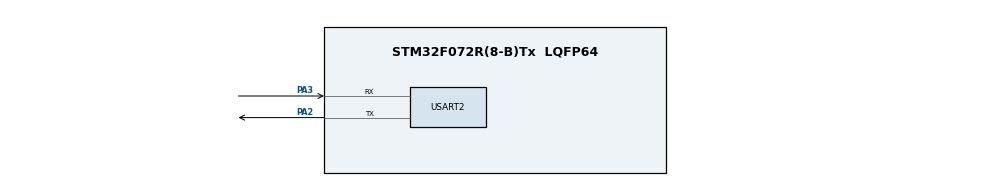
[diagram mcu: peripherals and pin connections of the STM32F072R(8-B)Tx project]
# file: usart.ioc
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Mcu.Family=STM32F0
Mcu.Name=STM32F072R(8-B)Tx
Mcu.Package=LQFP64
NVIC.USART2_IRQn=true\:0\:0\:false\:false\:true\:true\:true
PA2.Mode=Asynchronous
PA2.Signal=USART2_TX
PA3.Mode=Asynchronous
PA3.Signal=USART2_RX
ProjectManager.HeapSize=0x200
ProjectManager.StackSize=0x400
ProjectManager.TargetToolchain=MDK-ARM V5
USART2.VirtualMode-Asynchronous=VM_ASYNC
board=custom

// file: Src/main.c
/* USER CODE BEGIN Header */
/**
  ******************************************************************************
  * @file           : main.c
  * @brief          : Main program body
  ******************************************************************************
  * @attention
  *
  * <h2><center>&copy; Copyright (c) 2020 STMicroelectronics.
  * All rights reserved.</center></h2>
  *
  * This software component is licensed by ST under BSD 3-Clause license,
  * the "License"; You may not use this file except in compliance with the
  * License. You may obtain a copy of the License at:
  *                        opensource.org/licenses/BSD-3-Clause
  *
  ******************************************************************************
  */
/* USER CODE END Header */

#include "main.h"
#include "usart.h"
#include "gpio.h"

void SystemClock_Config(void);

int main(void)
{

  /* MCU Configuration--------------------------------------------------------*/

  /* Reset of all peripherals, Initializes the Flash interface and the Systick. */
  HAL_Init();

  /* Configure the system clock */
  SystemClock_Config();

  /* Initialize all configured peripherals */
  MX_GPIO_Init();
  MX_USART2_UART_Init();

  /* Infinite loop */
  while (1)
  {

    /* USER CODE BEGIN 3 */
    usart_polling();
  }
  /* USER CODE END 3 */
}

void SystemClock_Config(void)
{
  RCC_OscInitTypeDef RCC_OscInitStruct = {0};
  RCC_ClkInitTypeDef RCC_ClkInitStruct = {0};
  RCC_PeriphCLKInitTypeDef PeriphClkInit = {0};

  /** Initializes the CPU, AHB and APB busses clocks
  */
  RCC_OscInitStruct.OscillatorType = RCC_OSCILLATORTYPE_HSI;
  RCC_OscInitStruct.HSIState = RCC_HSI_ON;
  RCC_OscInitStruct.HSICalibrationValue = RCC_HSICALIBRATION_DEFAULT;
  RCC_OscInitStruct.PLL.PLLState = RCC_PLL_NONE;
  if (HAL_RCC_OscConfig(&RCC_OscInitStruct) != HAL_OK)
  {
    Error_Handler();
  }
  /** Initializes the CPU, AHB and APB busses clocks
  */
  RCC_ClkInitStruct.ClockType = RCC_CLOCKTYPE_HCLK|RCC_CLOCKTYPE_SYSCLK
                              |RCC_CLOCKTYPE_PCLK1;
  RCC_ClkInitStruct.SYSCLKSource = RCC_SYSCLKSOURCE_HSI;
  RCC_ClkInitStruct.AHBCLKDivider = RCC_SYSCLK_DIV1;
  RCC_ClkInitStruct.APB1CLKDivider = RCC_HCLK_DIV1;

  if (HAL_RCC_ClockConfig(&RCC_ClkInitStruct, FLASH_LATENCY_0) != HAL_OK)
  {
    Error_Handler();
  }
  PeriphClkInit.PeriphClockSelection = RCC_PERIPHCLK_USART2;
  PeriphClkInit.Usart2ClockSelection = RCC_USART2CLKSOURCE_PCLK1;
  if (HAL_RCCEx_PeriphCLKConfig(&PeriphClkInit) != HAL_OK)
  {
    Error_Handler();
  }
}

void Error_Handler(void)
{
}

/************************ (C) COPYRIGHT STMicroelectronics *****END OF FILE****/
